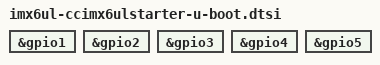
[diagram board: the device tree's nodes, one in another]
/*
 * Copyright (C) 2025, Digi International Inc.
 *
 * The code contained herein is licensed under the GNU General Public
 * License. You may obtain a copy of the GNU General Public License
 * Version 2 or later at the following locations:
 *
 * http://www.opensource.org/licenses/gpl-license.html
 * http://www.gnu.org/copyleft/gpl.html
 */

&gpio1 {
	bootph-some-ram;
};

&gpio2 {
	bootph-some-ram;
};

&gpio3 {
	bootph-some-ram;
};

&gpio4 {
	bootph-some-ram;
};

&gpio5 {
	bootph-some-ram;
};
